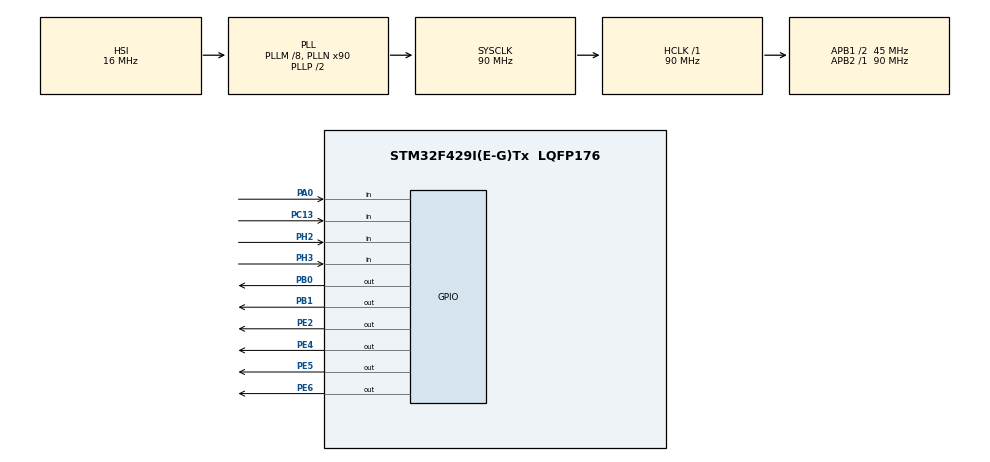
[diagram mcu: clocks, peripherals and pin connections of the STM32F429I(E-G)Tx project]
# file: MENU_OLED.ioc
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Mcu.Family=STM32F4
Mcu.Name=STM32F429I(E-G)Tx
Mcu.Package=LQFP176
NVIC.PriorityGroup=NVIC_PRIORITYGROUP_4
NVIC.RCC_IRQn=true\:0\:0\:false\:true\:true\:2\:true\:false\:true
NVIC.TIM2_IRQn=true\:1\:0\:true\:true\:true\:1\:true\:true\:true
NVIC.TIM3_IRQn=true\:0\:0\:false\:true\:true\:3\:true\:true\:true
PA0/WKUP.GPIO_PuPd=GPIO_PULLDOWN
PA0/WKUP.Signal=GPIO_Input
PA13.Mode=Serial_Wire
PA13.Signal=SYS_JTMS-SWDIO
PA14.Mode=Serial_Wire
PA14.Signal=SYS_JTCK-SWCLK
PB0.GPIO_Speed=GPIO_SPEED_FREQ_HIGH
PB0.PinState=GPIO_PIN_SET
PB0.Signal=GPIO_Output
PB1.GPIO_Speed=GPIO_SPEED_FREQ_HIGH
PB1.PinState=GPIO_PIN_SET
PB1.Signal=GPIO_Output
PC13.GPIO_PuPd=GPIO_PULLUP
PC13.Signal=GPIO_Input
PC14/OSC32_IN.Mode=LSE-External-Oscillator
PC14/OSC32_IN.Signal=RCC_OSC32_IN
PC15/OSC32_OUT.Mode=LSE-External-Oscillator
PC15/OSC32_OUT.Signal=RCC_OSC32_OUT
PE2.GPIO_PuPd=GPIO_PULLUP
PE2.GPIO_Speed=GPIO_SPEED_FREQ_HIGH
PE2.PinState=GPIO_PIN_SET
PE2.Signal=GPIO_Output
PE4.GPIO_Speed=GPIO_SPEED_FREQ_HIGH
PE4.Signal=GPIO_Output
PE5.GPIO_Speed=GPIO_SPEED_FREQ_HIGH
PE5.Signal=GPIO_Output
PE6.GPIO_Speed=GPIO_SPEED_FREQ_HIGH
PE6.Signal=GPIO_Output
PH0/OSC_IN.Mode=HSE-External-Oscillator
PH0/OSC_IN.Signal=RCC_OSC_IN
PH1/OSC_OUT.Mode=HSE-External-Oscillator
PH1/OSC_OUT.Signal=RCC_OSC_OUT
PH2.GPIO_PuPd=GPIO_PULLUP
PH2.Signal=GPIO_Input
PH3.GPIO_PuPd=GPIO_PULLUP
PH3.Signal=GPIO_Input
ProjectManager.HeapSize=0x200
ProjectManager.StackSize=0x400
ProjectManager.TargetToolchain=MDK-ARM V5.32
RCC.48MHZClocksFreq_Value=45000000
RCC.AHBFreq_Value=90000000
RCC.APB1CLKDivider=RCC_HCLK_DIV2
RCC.APB1Freq_Value=45000000
RCC.APB1TimFreq_Value=90000000
RCC.APB2Freq_Value=90000000
RCC.APB2TimFreq_Value=90000000
RCC.CortexFreq_Value=90000000
RCC.HCLKFreq_Value=90000000
RCC.HSE_VALUE=25000000
RCC.HSI_VALUE=16000000
RCC.PLLM=8
RCC.PLLN=90
RCC.RCC_RTC_Clock_Source=RCC_RTCCLKSOURCE_LSE
RCC.RCC_RTC_Clock_SourceVirtual=RCC_RTCCLKSOURCE_LSE
RCC.SYSCLKFreq_VALUE=90000000
RCC.SYSCLKSource=RCC_SYSCLKSOURCE_PLLCLK
RCC.VCOOutputFreq_Value=180000000
RTC.Date=12
RTC.Format=RTC_FORMAT_BIN
RTC.Hours=12
RTC.Minutes=32
RTC.Month=RTC_MONTH_DECEMBER
RTC.Seconds=56
RTC.WeekDay=RTC_WEEKDAY_SUNDAY
TIM2.Period=5000
TIM2.Prescaler=90-1
TIM3.AutoReloadPreload=TIM_AUTORELOAD_PRELOAD_ENABLE
TIM3.Prescaler=90-1
VP_RTC_VS_RTC_Activate.Mode=RTC_Enabled
VP_RTC_VS_RTC_Calendar.Mode=RTC_Calendar
VP_TIM2_VS_ClockSourceINT.Mode=Internal
VP_TIM3_VS_ClockSourceINT.Mode=Internal
board=custom

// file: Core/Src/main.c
/* USER CODE BEGIN Header */
/**
  ******************************************************************************
  * @file           : main.c
  * @brief          : Main program body
  ******************************************************************************
  * @attention
  *
  * Copyright (c) 2023 STMicroelectronics.
  * All rights reserved.
  *
  * This software is licensed under terms that can be found in the LICENSE file
  * in the root directory of this software component.
  * If no LICENSE file comes with this software, it is provided AS-IS.
  *
  ******************************************************************************
  */
/* USER CODE END Header */
#include "main.h"
#include "rtc.h"
#include "tim.h"
#include "gpio.h"

/* USER CODE BEGIN Includes */

#include "stdlib.h"
#include "oled.h"
#include "menu.h"
#include "dinogame.h"

/* USER CODE END Includes */

void SystemClock_Config(void);
static void MX_NVIC_Init(void);

int main(void)
{

  /* MCU Configuration--------------------------------------------------------*/

  /* Reset of all peripherals, Initializes the Flash interface and the Systick. */
  HAL_Init();

  /* Configure the system clock */
  SystemClock_Config();

  /* Initialize all configured peripherals */
  MX_GPIO_Init();
  MX_TIM2_Init();
  MX_RTC_Init();
  MX_TIM3_Init();

  /* Initialize interrupts */
  MX_NVIC_Init();
  /* USER CODE BEGIN 2 */
  OLED_Init();
  OLED_Clear();

  /* USER CODE END 2 */

  /* Infinite loop */
  while (1)
  {

    /* USER CODE BEGIN 3 */
	  Menu_key_set();

  }
  /* USER CODE END 3 */
}

void SystemClock_Config(void)
{
  RCC_OscInitTypeDef RCC_OscInitStruct = {0};
  RCC_ClkInitTypeDef RCC_ClkInitStruct = {0};

  /** Configure the main internal regulator output voltage
  */
  __HAL_RCC_PWR_CLK_ENABLE();
  __HAL_PWR_VOLTAGESCALING_CONFIG(PWR_REGULATOR_VOLTAGE_SCALE3);

  /** Initializes the RCC Oscillators according to the specified parameters
  * in the RCC_OscInitTypeDef structure.
  */
  RCC_OscInitStruct.OscillatorType = RCC_OSCILLATORTYPE_HSI|RCC_OSCILLATORTYPE_LSE;
  RCC_OscInitStruct.LSEState = RCC_LSE_ON;
  RCC_OscInitStruct.HSIState = RCC_HSI_ON;
  RCC_OscInitStruct.HSICalibrationValue = RCC_HSICALIBRATION_DEFAULT;
  RCC_OscInitStruct.PLL.PLLState = RCC_PLL_ON;
  RCC_OscInitStruct.PLL.PLLSource = RCC_PLLSOURCE_HSI;
  RCC_OscInitStruct.PLL.PLLM = 8;
  RCC_OscInitStruct.PLL.PLLN = 90;
  RCC_OscInitStruct.PLL.PLLP = RCC_PLLP_DIV2;
  RCC_OscInitStruct.PLL.PLLQ = 4;
  if (HAL_RCC_OscConfig(&RCC_OscInitStruct) != HAL_OK)
  {
    Error_Handler();
  }

  /** Activate the Over-Drive mode
  */
  if (HAL_PWREx_EnableOverDrive() != HAL_OK)
  {
    Error_Handler();
  }

  /** Initializes the CPU, AHB and APB buses clocks
  */
  RCC_ClkInitStruct.ClockType = RCC_CLOCKTYPE_HCLK|RCC_CLOCKTYPE_SYSCLK
                              |RCC_CLOCKTYPE_PCLK1|RCC_CLOCKTYPE_PCLK2;
  RCC_ClkInitStruct.SYSCLKSource = RCC_SYSCLKSOURCE_PLLCLK;
  RCC_ClkInitStruct.AHBCLKDivider = RCC_SYSCLK_DIV1;
  RCC_ClkInitStruct.APB1CLKDivider = RCC_HCLK_DIV2;
  RCC_ClkInitStruct.APB2CLKDivider = RCC_HCLK_DIV1;

  if (HAL_RCC_ClockConfig(&RCC_ClkInitStruct, FLASH_LATENCY_2) != HAL_OK)
  {
    Error_Handler();
  }
}

/**
  * @brief NVIC Configuration.
  * @retval None
  */
static void MX_NVIC_Init(void)
{
  /* TIM2_IRQn interrupt configuration */
  HAL_NVIC_SetPriority(TIM2_IRQn, 1, 0);
  HAL_NVIC_EnableIRQ(TIM2_IRQn);
  /* RCC_IRQn interrupt configuration */
  HAL_NVIC_SetPriority(RCC_IRQn, 0, 0);
  HAL_NVIC_EnableIRQ(RCC_IRQn);
  /* TIM3_IRQn interrupt configuration */
  HAL_NVIC_SetPriority(TIM3_IRQn, 0, 0);
  HAL_NVIC_EnableIRQ(TIM3_IRQn);
}

void Error_Handler(void)
{
  __disable_irq();
  while (1)
  {
  }
}
